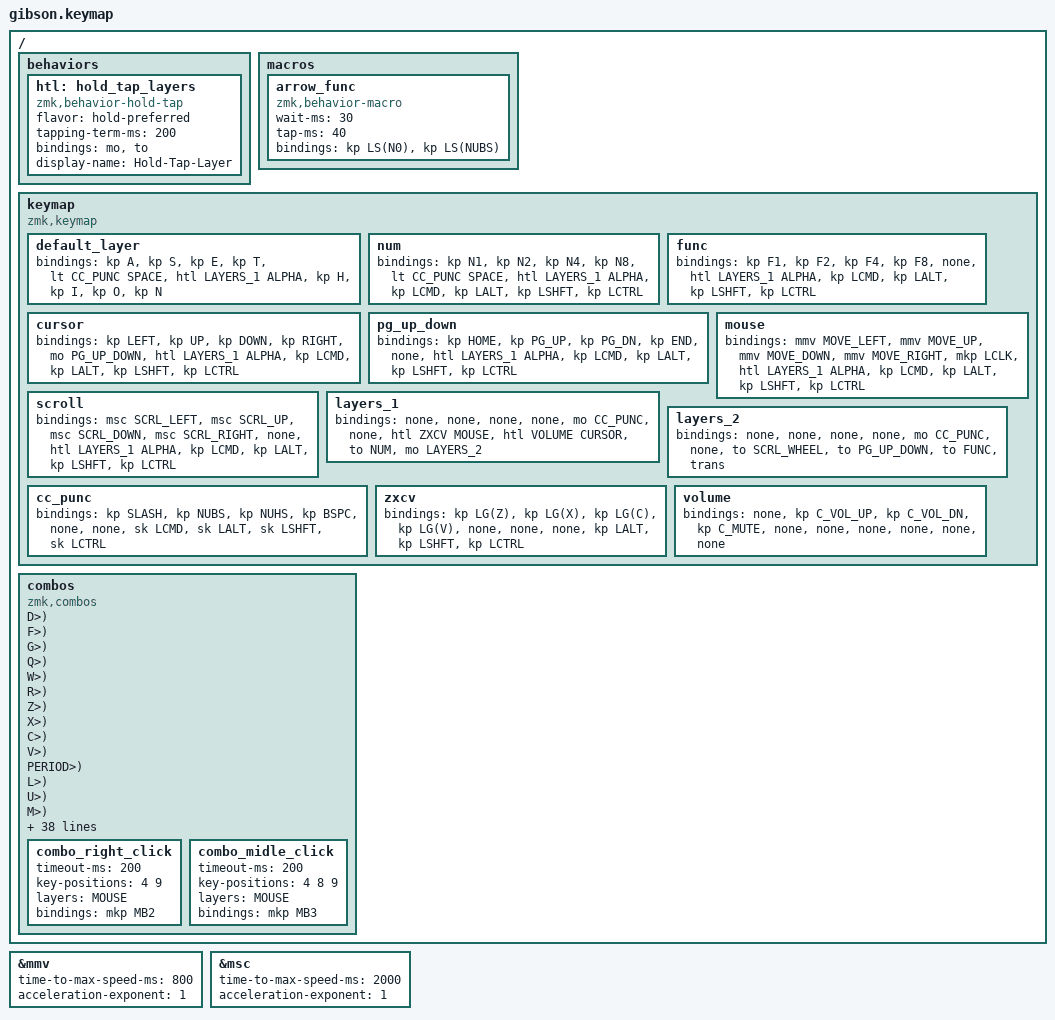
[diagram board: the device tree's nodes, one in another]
#include <behaviors.dtsi>
#include <dt-bindings/zmk/keys.h>
#include <dt-bindings/zmk/behaviors.h>

#define ZMK_POINTING_DEFAULT_MOVE_VAL 2000
#define ZMK_POINTING_DEFAULT_SCRL_VAL 30

#include <dt-bindings/zmk/pointing.h>

#define ALPHA      0
#define NUM        1
#define FUNC       2
#define CURSOR     3
#define PG_UP_DOWN 4
#define MOUSE      5
#define SCRL_WHEEL 6
#define LAYERS_1   7
#define LAYERS_2   8
#define CC_PUNC    9
#define ZXCV       10
#define VOLUME     11

#define COMBO(keypos, layer, binds) { \
    timeout-ms = <50>; \
    key-positions = keypos; \
    layers = <layer>; \
    bindings = binds; \
}

&mmv {
    time-to-max-speed-ms = <800>;
    acceleration-exponent = <1>;
};

&msc {
    time-to-max-speed-ms = <2000>;
    acceleration-exponent = <1>;
};

/ {
    behaviors {
        htl: hold_tap_layers {
            compatible = "zmk,behavior-hold-tap";
            #binding-cells = <2>;
            flavor = "hold-preferred";
            tapping-term-ms = <200>;
            bindings = <&mo>, <&to>;
            display-name = "Hold-Tap-Layer";
        };
    };

    macros {
        arrow_func: arrow_func {
            compatible = "zmk,behavior-macro";
            #binding-cells = <0>;
            wait-ms = <30>;
            tap-ms = <40>;
            bindings = <&kp LS(N0) &kp LS(NUBS)>;
        };
    };

    keymap {
        compatible = "zmk,keymap";

        default_layer {
            bindings = < &kp A  &kp S  &kp E  &kp T &lt CC_PUNC SPACE                                &htl LAYERS_1 ALPHA  &kp H  &kp I  &kp O  &kp N >;
        };
        num {
            bindings = < &kp N1  &kp N2  &kp N4  &kp N8  &lt CC_PUNC SPACE                           &htl LAYERS_1 ALPHA  &kp LCMD  &kp LALT  &kp LSHFT  &kp LCTRL>;
        };
        func {
            bindings = < &kp F1  &kp F2  &kp F4  &kp F8  &none                                       &htl LAYERS_1 ALPHA  &kp LCMD  &kp LALT  &kp LSHFT  &kp LCTRL>;
        };
        cursor {
            bindings = < &kp LEFT  &kp UP  &kp DOWN  &kp RIGHT  &mo PG_UP_DOWN                       &htl LAYERS_1 ALPHA  &kp LCMD  &kp LALT  &kp LSHFT  &kp LCTRL>;
        };
        pg_up_down {
            bindings = < &kp HOME  &kp PG_UP  &kp PG_DN  &kp END  &none                              &htl LAYERS_1 ALPHA  &kp LCMD  &kp LALT  &kp LSHFT  &kp LCTRL>;
        };
        mouse {
            bindings = < &mmv MOVE_LEFT  &mmv MOVE_UP  &mmv MOVE_DOWN  &mmv MOVE_RIGHT  &mkp LCLK    &htl LAYERS_1 ALPHA  &kp LCMD  &kp LALT  &kp LSHFT  &kp LCTRL>;
        };
        scroll {
            bindings = < &msc SCRL_LEFT  &msc SCRL_UP  &msc SCRL_DOWN  &msc SCRL_RIGHT  &none        &htl LAYERS_1 ALPHA  &kp LCMD  &kp LALT  &kp LSHFT  &kp LCTRL>;
        };
        layers_1 {
            bindings = < &none  &none  &none  &none  &mo CC_PUNC                                     &none  &htl ZXCV MOUSE  &htl VOLUME CURSOR &to NUM &mo LAYERS_2>;
        };
        layers_2 {
            bindings = < &none  &none  &none  &none  &mo CC_PUNC                                     &none  &to SCRL_WHEEL  &to PG_UP_DOWN &to FUNC &trans>;
        };
        cc_punc {
            bindings = < &kp SLASH  &kp NUBS  &kp NUHS  &kp BSPC  &none                              &none  &sk LCMD  &sk LALT  &sk LSHFT  &sk LCTRL>;
        };
        zxcv {
            bindings = < &kp LG(Z)  &kp LG(X)  &kp LG(C)  &kp LG(V)  &none                           &none  &none  &kp LALT  &kp LSHFT  &kp LCTRL>;
        };
        volume {
            bindings = < &none  &kp C_VOL_UP  &kp C_VOL_DN  &kp C_MUTE  &none                        &none  &none  &none  &none  &none>;
        };

    };

    combos {
        compatible = "zmk,combos";

        // ALPHA
        combo_d COMBO(<0 1>, ALPHA, <&kp D>);
        combo_f COMBO(<1 2>, ALPHA, <&kp F>);
        combo_g COMBO(<2 3>, ALPHA, <&kp G>);
        combo_q COMBO(<0 2>, ALPHA, <&kp Q>);
        combo_w COMBO(<1 3>, ALPHA, <&kp W>);
        combo_r COMBO(<0 3>, ALPHA, <&kp R>);
        combo_z COMBO(<1 2 3>, ALPHA, <&kp Z>);
        combo_x COMBO(<0 2 3>, ALPHA, <&kp X>);
        combo_c COMBO(<0 1 3>, ALPHA, <&kp C>);
        combo_v COMBO(<0 1 2>, ALPHA, <&kp V>);
        combo_dot COMBO(<0 1 2 3>, ALPHA, <&kp PERIOD>);
        combo_l COMBO(<6 7>, ALPHA, <&kp L>);
        combo_u COMBO(<7 8>, ALPHA, <&kp U>);
        combo_m COMBO(<8 9>, ALPHA, <&kp M>);
        combo_y COMBO(<6 8>, ALPHA, <&kp Y>);
        combo_k COMBO(<7 9>, ALPHA, <&kp K>);
        combo_p COMBO(<6 9>, ALPHA, <&kp P>);
        combo_j COMBO(<7 8 9>, ALPHA, <&kp J>);
        combo_a_dia COMBO(<6 8 9>, ALPHA, <&kp SINGLE_QUOTE>); // Ä
        combo_o_dia COMBO(<6 7 9>, ALPHA, <&kp SEMICOLON>); // Ö
        combo_b COMBO(<6 7 8>, ALPHA, <&kp B>);
        combo_comma COMBO(<6 7 8 9>, ALPHA, <&kp COMMA>);

        // CC_PUNC
        combo_plus COMBO(<0 1>, CC_PUNC, <&kp MINUS>);
        combo_arrow COMBO(<1 2>, CC_PUNC, <&arrow_func>);
        combo_tab COMBO(<2 3>, CC_PUNC, <&kp TAB>);
        combo_dia COMBO(<0 2>, CC_PUNC, <&kp RIGHT_BRACKET>);
        combo_caps_word COMBO(<0 3>, CC_PUNC, <&caps_word>);
        combo_enter COMBO(<1 2 3>, CC_PUNC, <&kp ENTER>);
        combo_a_rng COMBO(<0 2 3>, CC_PUNC, <&kp LEFT_BRACKET>); // Å
        combo_acut COMBO(<0 1 2>, CC_PUNC, <&kp EQUAL>); // ´
        combo_esc COMBO(<0 1 2 3>, CC_PUNC, <&kp ESC>); // ´

        // NUM
        combo_3 COMBO(<0 1>, NUM, <&kp N3>);
        combo_5 COMBO(<0 2>, NUM, <&kp N5>);
        combo_6 COMBO(<1 2>, NUM, <&kp N6>);
        combo_7 COMBO(<0 1 2>, NUM, <&kp N7>);
        combo_9 COMBO(<0 3>, NUM, <&kp N9>);
        combo_0 COMBO(<1 3>, NUM, <&kp N0>);
        combo_divide COMBO(<0 1 3>, NUM, <&kp KP_DIVIDE>);
        combo_minus COMBO(<2 3>, NUM, <&kp KP_MINUS>);
        combo_multiply COMBO(<0 2 3>, NUM, <&kp KP_MULTIPLY>);
        combo_kp_plus COMBO(<1 2 3>, NUM, <&kp KP_PLUS>);
        combo_kp_dot COMBO(<0 1 2 3>, NUM, <&kp PERIOD>);

        // FUNC
        combo_f3 COMBO(<0 1>, FUNC, <&kp F3>);
        combo_f5 COMBO(<0 2>, FUNC, <&kp F5>);
        combo_f6 COMBO(<1 2>, FUNC, <&kp F6>);
        combo_f7 COMBO(<0 1 2>, FUNC, <&kp F7>);
        combo_f9 COMBO(<0 3>, FUNC, <&kp F9>);
        combo_f10 COMBO(<1 3>, FUNC, <&kp F10>);
        combo_f11 COMBO(<0 1 3>, FUNC, <&kp F11>);
        combo_f12 COMBO(<2 3>, FUNC, <&kp F12>);
        combo_f13 COMBO(<0 2 3>, FUNC, <&kp F13>);
        combo_f14 COMBO(<1 2 3>, FUNC, <&kp F14>);
        combo_f15 COMBO(<0 1 2 3>, FUNC, <&kp F15>);

        // MOUSE
        combo_right_click {
            timeout-ms = <200>;
            key-positions = <4 9>;
            layers = <MOUSE>;
            bindings = <&mkp MB2>;
        };
        combo_midle_click {
            timeout-ms = <200>;
            key-positions = <4 8 9>;
            layers = <MOUSE>;
            bindings = <&mkp MB3>;
        };


    };
};
